# STM32C593 register map
File version: 1.0.0
CPU: CM33 r0p4, little endian, MPU, FPU, 4 interrupt priority bits
Registers are 32-bit, read-write, reset 0x0 unless marked. A register's access mark holds for its fields unless they carry their own. Offsets are from the block's base; [hi:lo] are bit positions; {n}, {i} and the like mark numbered series.

## DLYB — DLYB register block
Base 0x4600F000
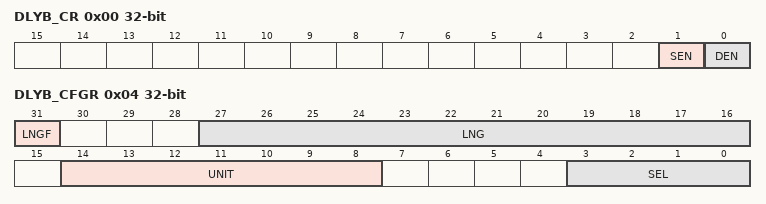
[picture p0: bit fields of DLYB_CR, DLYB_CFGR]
0x00 DLYB_CR — DLYB control register
  [1] SEN — Sampler length enable bit
    0=Sampler length and register access to UNIT[6:0] and SEL[3:0] disabled, output clock enabled; 1=Sampler length and register access to UNIT[6:0] and SEL[3:0] enabled, output clock disabled
  [0] DEN — Delay block enable bit
    0=DLYB disabled; 1=DLYB enabled
0x04 DLYB_CFGR — DLYB configuration register
  [31] LNGF ro — Length valid flag
    0=Length value in LNG is not valid; 1=Length value in LNG is valid
  [27:16] LNG ro — Delay line length value
  [14:8] UNIT — Delay of a unit delay cell.
  [3:0] SEL — Phase for the output clock.

## GPIOA — GPIO address block description
Base 0x42020000
Same registers: GPIOB 0x42020400, GPIOC 0x42020800, GPIOD 0x42020C00, GPIOE 0x42021000, GPIOF 0x42021400, GPIOG 0x42021800, GPIOH 0x42021C00
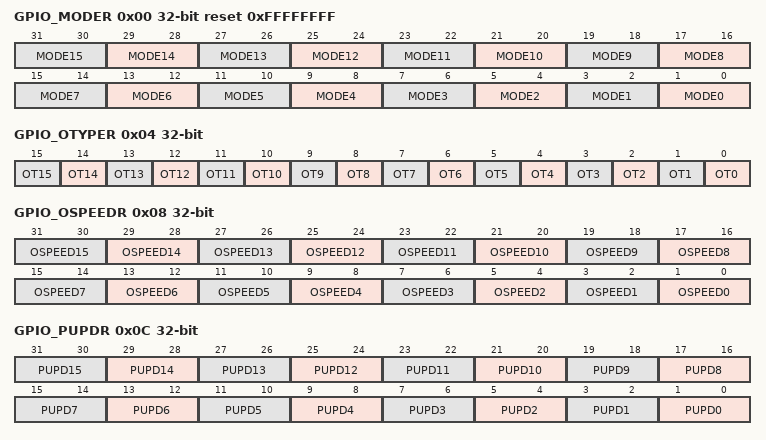
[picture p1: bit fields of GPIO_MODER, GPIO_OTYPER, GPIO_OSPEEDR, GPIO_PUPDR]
0x00 GPIO_MODER reset 0xFFFFFFFF — GPIO port mode register
  [all] fields
    0=Input mode; 1=General purpose output mode; 2=Alternate function mode; 3=Analog mode (reset state)
  [2n+1:2n] MODE{n} (n=0..15) — Port x configuration I/O pin y
0x04 GPIO_OTYPER — GPIO port output type register
  [all] fields
    0=Output push-pull (reset state); 1=Output open-drain
  [n] OT{n} (n=0..15) — Port x configuration I/O pin y
0x08 GPIO_OSPEEDR — GPIO port output speed register
  [all] fields
    0=Low speed; 1=Medium speed; 2=High speed; 3=Very-high speed
  [2n+1:2n] OSPEED{n} (n=0..15) — Port x configuration I/O pin y
0x0C GPIO_PUPDR — GPIO port pull-up/pull-down register
  [all] fields
    0=No pull-up, pull-down; 1=Pull-up; 2=Pull-down
  [2n+1:2n] PUPD{n} (n=0..15) — Port x configuration I/O pin y
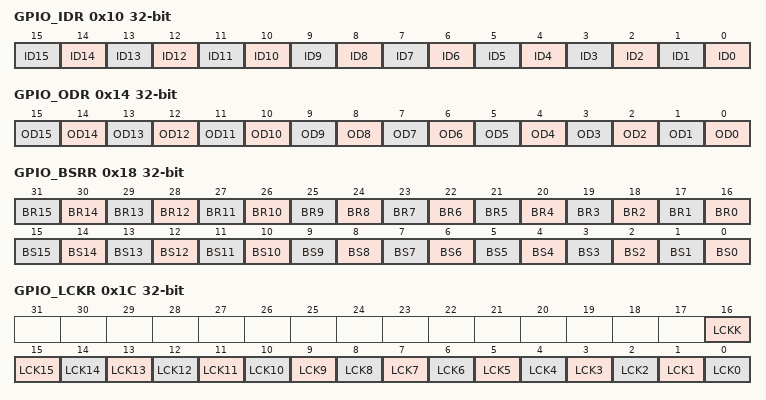
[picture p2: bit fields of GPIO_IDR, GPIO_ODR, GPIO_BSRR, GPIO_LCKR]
0x10 GPIO_IDR ro (reset mask 0xFFFF0000) — GPIO port input data register
  [n] ID{n} (n=0..15) — Port x input data I/O pin y
0x14 GPIO_ODR — GPIO port output data register
  [n] OD{n} (n=0..15) — Port output data I/O pin y
0x18 GPIO_BSRR wo — GPIO port bit set/reset register
  [n+16] BR{n} (n=0..15) — Port x reset I/O pin y
    0=No action on the corresponding ODy bit; 1=Resets the corresponding ODy bit
  [n] BS{n} (n=0..15) — Port x set I/O pin y
    0=No action on the corresponding ODy bit; 1=Sets the corresponding ODy bit
0x1C GPIO_LCKR — GPIO port configuration lock register
  [16] LCKK — Lock key
    0=Port configuration lock key not active; 1=Port configuration lock key active
  [n] LCK{n} (n=0..15) — Port x lock I/O pin y
    0=Port configuration not locked; 1=Port configuration locked
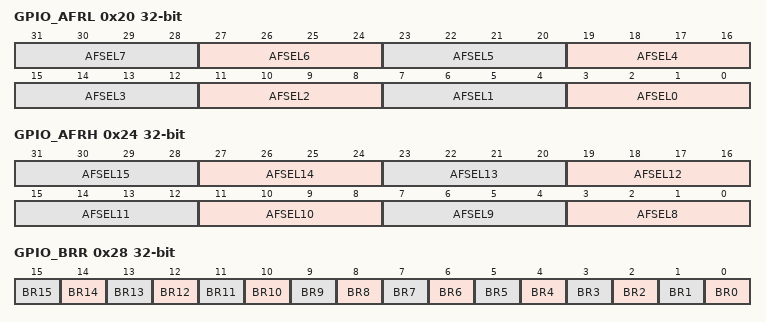
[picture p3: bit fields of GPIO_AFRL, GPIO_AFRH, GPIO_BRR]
0x20 GPIO_AFRL — GPIO alternate function low register
  [all] fields
    {v}=AF{v} (v=0..15)
  [4n+3:4n] AFSEL{n} (n=0..7) — Alternate function selection for port x I/O pin y
0x24 GPIO_AFRH — GPIO alternate function high register
  [all] fields
    {v}=AF{v} (v=0..15)
  [4n-29:4n-32] AFSEL{n} (n=8..15) — Alternate function selection for port x I/O pin y
0x28 GPIO_BRR wo — GPIO port bit reset register
  [all] fields
    0=No action on the corresponding ODy bit; 1=Reset the corresponding ODy bit
  [n] BR{n} (n=0..15) — Port x reset IO pin y

## HASH — HASH register bank
Base 0x420C0400
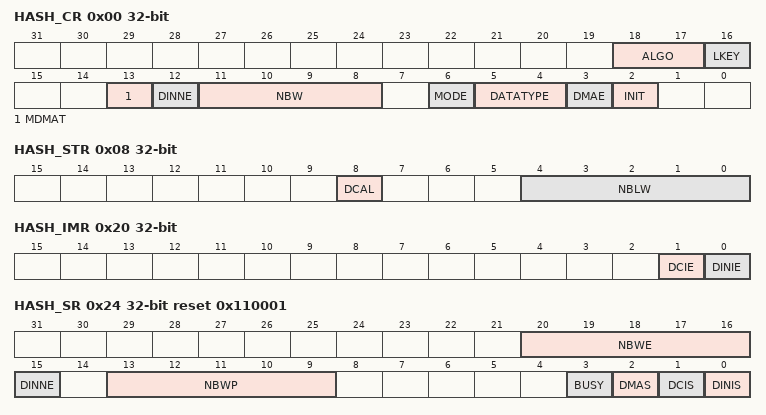
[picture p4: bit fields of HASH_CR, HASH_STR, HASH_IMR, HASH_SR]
0x00 HASH_CR — HASH control register
  [18:17] ALGO — Algorithm selection
    0=SHA-1; 2=SHA-224; 3=SHA-256
  [16] LKEY — Long key selection
    0=HMAC key is shorter or equal to the block size (short key); 1=HMAC key is longer than the block size (long key)
  [13] MDMAT — Multiple DMA transfers
    0=DCAL is automatically set at the end of a DMA transfer; 1=DCAL is not automatically set at the end of a DMA transfer
  [12] DINNE ro — DIN not empty
  [11:8] NBW ro — Number of words already pushed
  [6] MODE — Mode selection
    0=Hash mode selected; 1=HMAC mode selected
  [5:4] DATATYPE — Data type selection
    0=32-bit data; 1=16-bit data or half-word; 2=8-bit data or bytes; 3=bit data or bit string
  [3] DMAE — DMA enable
    0=DMA transfers disabled; 1=DMA transfers enabled
  [2] INIT — Initialize message digest calculation
0x04 HASH_DIN wo — HASH data input register
  [31:0] DATAIN — Data input
0x08 HASH_STR — HASH start register
  [8] DCAL — Digest calculation
  [4:0] NBLW — Number of valid bits in the last word
    0=All the 32 bits of the last data written are valid message bits, that is M[31:0]; 1=Only one bit of the last data written (after swapping) is valid, that is M[0]; 2=Only two bits of the last data written (after swapping) are valid, that is M[1:0]; 3=Only three bits of the last data written (after swapping) are valid that is M[2:0]; 31=Only 31 bits of the last data written (after swapping) are valid that is M[30:0]
{0xC+4i} HASH_HRA{i} ro (i=0..4) — HASH aliased digest register {i}
  [31:0] H{i} — Hash data x
0x20 HASH_IMR — HASH interrupt enable register
  [1] DCIE — Digest calculation completion interrupt enable
    0=Digest calculation completion interrupt disabled; 1=Digest calculation completion interrupt enabled
  [0] DINIE — Data input interrupt enable
    0=Data input interrupt disabled; 1=Data input interrupt enabled
0x24 HASH_SR reset 0x110001 — HASH status register
  [20:16] NBWE ro — Number of words expected
  [15] DINNE ro — DIN not empty
    0=No data are present in the data input buffer; 1=The input buffer contains at least one word of data
  [13:9] NBWP ro — Number of words already pushed
  [3] BUSY ro — Busy bit
    0=No block is currently being processed; 1=The hash core is processing a block of data
  [2] DMAS ro — DMA Status
    0=DMA interface is disabled (DMAE=0) and no transfer is ongoing; 1=DMA interface is enabled (DMAE=1) or a transfer is ongoing
  [1] DCIS — Digest calculation completion interrupt status
    0=No digest available in the HASH_HRx registers (zeros are returned); 1=Digest calculation complete, a digest is available in the HASH_HRx registers
  [0] DINIS — Data input interrupt status
    0=Less than 16 locations are free in the input buffer; 1=A new block can be entered into the input buffer
{0xF8+4i} HASH_CSR{i} (i=0..53) — HASH context swap register {i}
  [31:0] CS{i} — Context swap x
{0x310+4i} HASH_HR{i} ro (i=0..4) — HASH digest register {i}
  [31:0] H{i} — Hash data x
{0x310+4i} HASH_HR{i} ro (i=5..7) — HASH supplementary digest register {i}
  [31:0] H{i} — Hash data x
